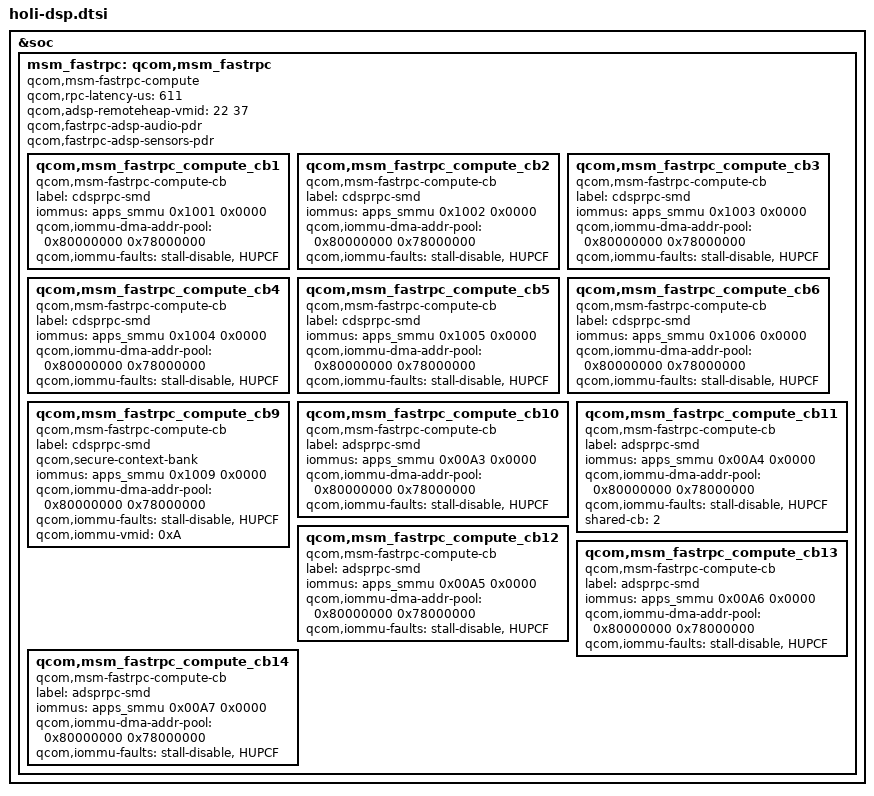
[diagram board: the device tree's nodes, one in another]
&soc {

	msm_fastrpc: qcom,msm_fastrpc {
		compatible = "qcom,msm-fastrpc-compute";
		qcom,rpc-latency-us = <611>;
		qcom,adsp-remoteheap-vmid = <22 37>;
		qcom,fastrpc-adsp-audio-pdr;
		qcom,fastrpc-adsp-sensors-pdr;

		qcom,msm_fastrpc_compute_cb1 {
			compatible = "qcom,msm-fastrpc-compute-cb";
			label = "cdsprpc-smd";
			iommus = <&apps_smmu 0x1001 0x0000>;
			qcom,iommu-dma-addr-pool = <0x80000000 0x78000000>;
			qcom,iommu-faults = "stall-disable", "HUPCF";
		};

		qcom,msm_fastrpc_compute_cb2 {
			compatible = "qcom,msm-fastrpc-compute-cb";
			label = "cdsprpc-smd";
			iommus = <&apps_smmu 0x1002 0x0000>;
			qcom,iommu-dma-addr-pool = <0x80000000 0x78000000>;
			qcom,iommu-faults = "stall-disable", "HUPCF";
		};

		qcom,msm_fastrpc_compute_cb3 {
			compatible = "qcom,msm-fastrpc-compute-cb";
			label = "cdsprpc-smd";
			iommus = <&apps_smmu 0x1003 0x0000>;
			qcom,iommu-dma-addr-pool = <0x80000000 0x78000000>;
			qcom,iommu-faults = "stall-disable", "HUPCF";
		};

		qcom,msm_fastrpc_compute_cb4 {
			compatible = "qcom,msm-fastrpc-compute-cb";
			label = "cdsprpc-smd";
			iommus = <&apps_smmu 0x1004 0x0000>;
			qcom,iommu-dma-addr-pool = <0x80000000 0x78000000>;
			qcom,iommu-faults = "stall-disable", "HUPCF";
		};

		qcom,msm_fastrpc_compute_cb5 {
			compatible = "qcom,msm-fastrpc-compute-cb";
			label = "cdsprpc-smd";
			iommus = <&apps_smmu 0x1005 0x0000>;
			qcom,iommu-dma-addr-pool = <0x80000000 0x78000000>;
			qcom,iommu-faults = "stall-disable", "HUPCF";
		};

		qcom,msm_fastrpc_compute_cb6 {
			compatible = "qcom,msm-fastrpc-compute-cb";
			label = "cdsprpc-smd";
			iommus = <&apps_smmu 0x1006 0x0000>;
			qcom,iommu-dma-addr-pool = <0x80000000 0x78000000>;
			qcom,iommu-faults = "stall-disable", "HUPCF";
		};

		qcom,msm_fastrpc_compute_cb9 {
			compatible = "qcom,msm-fastrpc-compute-cb";
			label = "cdsprpc-smd";
			qcom,secure-context-bank;
			iommus = <&apps_smmu 0x1009 0x0000>;
			qcom,iommu-dma-addr-pool = <0x80000000 0x78000000>;
			qcom,iommu-faults = "stall-disable", "HUPCF";
			qcom,iommu-vmid = <0xA>;       /* VMID_CP_PIXEL */
		};

		qcom,msm_fastrpc_compute_cb10 {
			compatible = "qcom,msm-fastrpc-compute-cb";
			label = "adsprpc-smd";
			iommus = <&apps_smmu 0x00A3 0x0000>;
			qcom,iommu-dma-addr-pool = <0x80000000 0x78000000>;
			qcom,iommu-faults = "stall-disable", "HUPCF";
		};

		qcom,msm_fastrpc_compute_cb11 {
			compatible = "qcom,msm-fastrpc-compute-cb";
			label = "adsprpc-smd";
			iommus = <&apps_smmu 0x00A4 0x0000>;
			qcom,iommu-dma-addr-pool = <0x80000000 0x78000000>;
			qcom,iommu-faults = "stall-disable", "HUPCF";
			shared-cb = <2>;
		};

		qcom,msm_fastrpc_compute_cb12 {
			compatible = "qcom,msm-fastrpc-compute-cb";
			label = "adsprpc-smd";
			iommus = <&apps_smmu 0x00A5 0x0000>;
			qcom,iommu-dma-addr-pool = <0x80000000 0x78000000>;
			qcom,iommu-faults = "stall-disable", "HUPCF";
		};

		qcom,msm_fastrpc_compute_cb13 {
			compatible = "qcom,msm-fastrpc-compute-cb";
			label = "adsprpc-smd";
			iommus = <&apps_smmu 0x00A6 0x0000>;
			qcom,iommu-dma-addr-pool = <0x80000000 0x78000000>;
			qcom,iommu-faults = "stall-disable", "HUPCF";
		};

		qcom,msm_fastrpc_compute_cb14 {
			compatible = "qcom,msm-fastrpc-compute-cb";
			label = "adsprpc-smd";
			iommus = <&apps_smmu 0x00A7 0x0000>;
			qcom,iommu-dma-addr-pool = <0x80000000 0x78000000>;
			qcom,iommu-faults = "stall-disable", "HUPCF";
		};
	};
};

